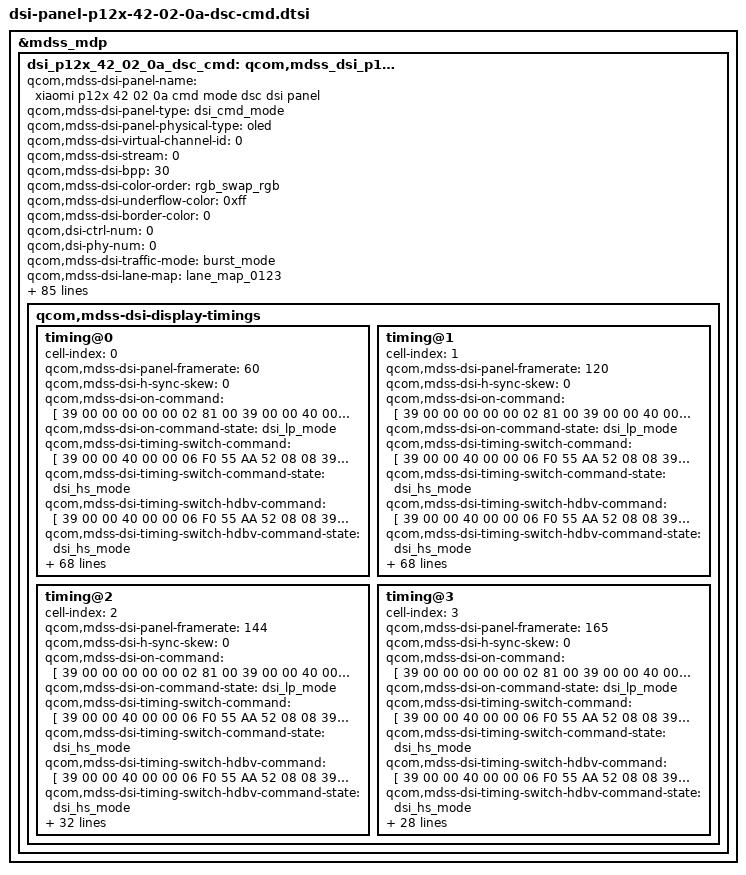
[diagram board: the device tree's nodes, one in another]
&mdss_mdp {
	dsi_p12x_42_02_0a_dsc_cmd: qcom,mdss_dsi_p12x_42_02_0a_dsc_cmd {
		qcom,mdss-dsi-panel-name = "xiaomi p12x 42 02 0a cmd mode dsc dsi panel";
		qcom,mdss-dsi-panel-type = "dsi_cmd_mode";
		qcom,mdss-dsi-panel-physical-type = "oled";
		qcom,mdss-dsi-virtual-channel-id = <0>;
		qcom,mdss-dsi-stream = <0>;
		qcom,mdss-dsi-bpp = <30>;
		qcom,mdss-dsi-color-order = "rgb_swap_rgb";
		qcom,mdss-dsi-underflow-color = <0xff>;
		qcom,mdss-dsi-border-color = <0>;
		qcom,dsi-ctrl-num = <0>;
		qcom,dsi-phy-num = <0>;
		qcom,mdss-dsi-traffic-mode = "burst_mode";
		qcom,mdss-dsi-lane-map = "lane_map_0123";
		qcom,mdss-dsi-bllp-eof-power-mode;
		qcom,mdss-dsi-bllp-power-mode;
		qcom,mdss-dsi-lane-0-state;
		qcom,mdss-dsi-lane-1-state;
		qcom,mdss-dsi-lane-2-state;
		qcom,mdss-dsi-lane-3-state;
		qcom,mdss-dsi-dma-trigger = "trigger_sw";
		qcom,mdss-dsi-mdp-trigger = "none";
		qcom,mdss-dsi-reset-sequence =<1 5>, <0 5>, <1 10>;
		qcom,mdss-pan-physical-width-dimension = <727>;
		qcom,mdss-pan-physical-height-dimension = <1575>;
		qcom,mdss-dsi-te-pin-select = <1>;
		qcom,mdss-dsi-wr-mem-start = <0x2c>;
		qcom,mdss-dsi-wr-mem-continue = <0x3c>;
		qcom,mdss-dsi-te-dcs-command = <1>;
		qcom,mdss-dsi-te-check-enable;
		qcom,mdss-dsi-te-using-te-pin;
		qcom,mdss-dsi-tx-eot-append;
		qcom,mdss-dsi-lp11-init;
		qcom,mdss-dsi-bl-inverted-dbv;
		qcom,mdss-dsi-panel-dimming-enabled;
		qcom,bl-update-flag = "delay_until_first_frame";
		qcom,mdss-dsi-panel-hdr-enabled;
		qcom,mdss-dsi-panel-hdr-color-primaries = <14500 15500 32000
			17000 15500 30000 8000 3000>;
		qcom,mdss-dsi-panel-peak-brightness = <32000000>;
		qcom,mdss-dsi-panel-blackness-level = <3230>;
		qcom,mdss-dsi-dma-schedule-line = <1>;
		qcom,mdss-dsi-dma-schedule-window = <50>;
		mi,panel-id = <0x50313258 0x0042020A>;
		mi,panel-on-dimming-delay = <120>;

		/* IRQF_ONESHOT | IRQF_TRIGGER_LOW */
		mi,esd-err-irq-gpio = <&tlmm 87 0x2008>;
		mi,esd-err-irq-gpio-flag = <0x2008>;

		mi,mdss-dsi-panel-wp-read-command = [06 01 00 01 00 00 01 5C];
		mi,mdss-dsi-panel-wp-read-command-state = "dsi_hs_mode";
		mi,mdss-dsi-panel-wp-read-length = <8>;

		mi,mdss-dsi-panel-cell-id-read-command = [06 01 00 01 00 00 01 5A];
		mi,mdss-dsi-panel-cell-id-read-command-state = "dsi_hs_mode";
		mi,mdss-dsi-panel-cell-id-read-length = <14>;
		mi,max-brightness-clone = <16383>;
		mi,mdss-dsi-fac-bl-max-level = <8191>;
		mi,mdss-fac-brightness-max-level = <8191>;
		mi,flatmode-status-check-enabled;
		mi,mdss-dsi-panel-flatmode-status-offset-command = [
 			39 00 00 00 00 00 03 F0 AA 11
 		];
		mi,mdss-dsi-panel-flatmode-status-offset-command-state = "dsi_hs_mode";
		mi,mdss-dsi-panel-flatmode-status-command = [
				06 01 00 01 00 00 01 D5
		];
		mi,mdss-dsi-panel-flatmode-status-command-state = "dsi_hs_mode";
		mi,mdss-dsi-panel-flatmode-status-read-length = <1>;
		mi,mdss-dsi-panel-flatmode-on-status-value = <0x13>;

		mi,doze-hbm-dbv-level = <690>;
		mi,doze-lbm-dbv-level = <101>;
		mi,ddic-round-corner-enabled;
		qcom,mdss-disable-cesta-hw-sleep;

		qcom,mdss-dsi-display-timings {
			timing@0 {
				#include "dsi-panel-p12x-42-02-0a-dsc-cmd-common.dtsi"
				cell-index = <0>;
				qcom,mdss-dsi-panel-framerate = <60>;
				qcom,mdss-dsi-h-sync-skew = <0>;
				qcom,mdss-dsi-on-command = [
					39 00 00 00 00 00 02 81 00
					39 00 00 40 00 00 06 F0 55 AA 52 08 00
					39 00 00 40 00 00 02 6F 78
					39 00 00 40 00 00 18 B0 11 00 2A 00 C2 01 DA 03 7C 05 B1 08 80 0B EE 0F FF 05 55 05 56 05 55
					39 00 00 40 00 00 02 6F 6F
					39 00 00 40 00 00 07 B0 02 80 05 00 02 80
					39 00 00 40 00 00 06 F0 55 AA 52 08 08
					39 00 00 40 00 00 17 C1 8C FF CC FF FF CC FF FF CC FF FF EE 7F 7F EE 7F 7F FF 7F FF 0E 7F
					39 00 00 40 00 00 02 6F 20
					39 00 00 40 00 00 04 C1 4F 00 FF
					39 00 00 40 00 00 02 6F 23
					39 00 00 00 00 00 15 C1 0C FF CC FF FF CC FF FF CC FF FF EE 7F 7F EE 7F 7F CF 7F 30
					39 00 00 40 00 00 06 F0 55 AA 52 08 00
					39 00 00 40 00 00 02 C7 44
					39 00 00 40 00 00 02 6F 31
					39 00 00 00 00 00 03 C0 01 23
					39 00 00 40 00 00 02 6F 35
					39 00 00 00 00 00 03 C0 00 00
					39 00 00 40 00 00 06 F0 55 AA 52 08 04
					39 00 00 00 00 00 02 C0 20
					39 00 00 40 00 00 06 F0 55 AA 52 08 04
					39 00 00 40 00 00 02 B1 01
					39 00 00 40 00 00 02 6F 07
					39 00 00 40 00 00 04 B1 00 02 1C
					39 00 00 40 00 00 02 6F 0A
					39 00 00 40 00 00 02 B1 20
					39 00 00 40 00 00 02 6F 0B
					39 00 00 40 00 00 02 B1 02
					39 00 00 40 00 00 02 C4 10
					39 00 00 40 00 00 02 6F 02
					39 00 00 40 00 00 03 B5 14 23
					39 00 00 40 00 00 02 6F 06
					39 00 00 40 00 00 02 B5 00
					39 00 00 40 00 00 02 6F 19
					39 00 00 00 00 00 06 B8 24 50 00  35 9A
					39 00 00 40 00 00 05 2A 00 00 04 FF
					39 00 00 00 00 00 05 2B 00 00 0A D3
					39 00 00 40 00 00 03 90 03 43
					39 00 00 00 00 00 13 91 AB A8 00 0C C2 00 02 41 01 38 00 08 08 BB 07 21 10 F0
					39 00 00 40 00 00 02 2F 00
					39 00 00 40 00 00 03 5F 00 40
					39 00 00 00 00 00 02 35 00
					39 00 00 40 00 00 06 F0 55 AA 52 08 00
					39 00 00 40 00 00 05 BE 47 46 49 4C
					39 00 00 40 00 00 02 6F 26
					39 00 00 40 00 00 08 44 00 33 00 33 4B 03 A4
					39 00 00 40 00 00 02 6F 34
					39 00 00 40 00 00 08 44 00 0C 00 0C 4B 03 A4
					39 00 00 40 00 00 02 6F 02
					39 00 00 40 00 00 02 35 00
					39 00 00 40 00 00 02 6F 14
					39 00 00 40 00 00 04 35 63 E3 7D
					39 00 00 40 00 00 02 6F 2D
					39 00 00 40 00 00 08 44 00 AB 00 AB AB 03 AB
					39 00 00 40 00 00 02 6F 3B
					39 00 00 40 00 00 08 44 00 2C 00 2C 2C 03 AB
					39 00 00 40 00 00 02 6F 02
					39 00 00 40 00 00 02 35 00
					39 00 00 40 00 00 06 F0 55 AA 52 08 00
					39 00 00 40 00 00 02 6F 11
					39 00 00 00 00 00 02 BE 5F
					39 00 00 40 00 00 05 FF AA 55 A5 80
					39 00 00 40 00 00 02 6F 07
					39 00 00 40 00 00 02 F8 4D
					39 00 00 40 00 00 02 6F 23
					39 00 00 00 00 00 02 F8 4D
					39 00 00 40 00 00 05 FF AA 55 A5 81
					39 00 00 40 00 00 02 6F 0D
					39 00 00 40 00 00 02 FD 40
					39 00 00 40 00 00 03 51 00 05
					39 00 00 40 00 00 02 A2 03
					39 00 00 00 00 00 06 A3 84 02 2B 02 2B
					39 00 00 40 00 00 02 6F 04
					39 00 00 00 00 00 03 51 3F FF
					39 00 00 40 00 00 06 F0 55 AA 52 08 00
					39 00 00 40 00 00 02 6F 01
					39 00 00 40 00 00 02 BE 45
					39 00 00 40 00 00 02 6F 05
					39 00 00 40 00 00 02 BE 88
					39 00 00 00 00 00 02 53 20
					/* Video trim setting start */
					39 00 00 40 00 00 05 FF AA 55 A5 80
					39 00 00 40 00 00 02 6F 07
					39 00 00 40 00 00 02 F8 4D
					39 00 00 40 00 00 02 6F 23
					39 00 00 00 00 00 02 F8 4D
					39 00 00 40 00 00 06 F0 55 AA 52 08 01
					39 00 00 40 00 00 02 6F 2F
					39 00 00 40 00 00 02 C3 44
					39 00 00 40 00 00 02 6F 00
					39 00 00 40 00 00 02 C3 99
					39 00 00 40 00 00 02 6F 30
					39 00 00 40 00 00 02 C3 00
					39 00 00 40 00 00 02 6F 0B
					39 00 00 00 00 00 04 C3 3F 28 5B
					39 00 00 40 00 00 02 6F 11
					39 00 00 00 00 00 04 C3 3F 34 5B
					39 00 00 40 00 00 02 6F 17
					39 00 00 00 00 00 04 C3 3F 3C 5B
					39 00 00 40 00 00 02 6F 1D
					39 00 00 00 00 00 04 C3 3F 26 5B
					39 00 00 40 00 00 02 6F 23
					39 00 00 00 00 00 04 C3 3F 2F 5B
					39 00 00 40 00 00 02 6F 0E
					39 00 00 00 00 00 04 C3 3F 32 FF
					39 00 00 40 00 00 02 6F 14
					39 00 00 00 00 00 04 C3 3F 32 FF
					39 00 00 40 00 00 02 6F 1A
					39 00 00 00 00 00 04 C3 3F 32 FF
					39 00 00 40 00 00 02 6F 20
					39 00 00 00 00 00 04 C3 3F 32 FF
					39 00 00 40 00 00 02 6F 26
					39 00 00 00 00 00 04 C3 3F 32 FF
					39 00 00 40 00 00 02 6F 29
					39 00 00 00 00 00 04 C3 11 11 01
					39 00 00 40 00 00 02 6F 2C
					39 00 00 00 00 00 04 C3 00 00 00
					39 00 00 40 00 00 02 6F 31
					39 00 00 00 00 00 03 C3 AA 02
					39 00 00 40 00 00 02 6F 33
					39 00 00 00 00 00 03 C3 AA 02
					39 00 00 40 00 00 02 6F 04
					39 00 00 40 00 00 02 C3 19
					39 00 00 40 00 00 02 6F 09
					39 00 00 40 00 00 02 C3 19
					39 00 00 40 00 00 02 6F 01
					39 00 00 40 00 00 02 C3 09
					39 00 00 40 00 00 02 6F 06
					39 00 00 40 00 00 02 C3 09
					39 00 00 40 00 00 02 6F 02
					39 00 00 00 00 00 03 C3 02 81
					39 00 00 40 00 00 02 6F 08
					39 00 00 00 00 00 02 C3 81
					/* Video trim setting end */
					39 00 00 40 00 00 06 F0 55 AA 52 08 00
					39 00 00 40 00 00 02 6F DF
					39 00 00 40 00 00 06 B2 00 01 00 26 01
					39 00 00 40 00 00 02 6F 2B
					39 00 00 40 00 00 15 B2 00 00 2E B3 2E B3 2E B3 3F FF 3F FF 3F FF 3F FF 3F FF 3F FF
					39 00 00 40 00 00 02 6F 34
					39 00 00 00 00 00 15 B3 00 01 00 05 00 05 00 26 00 26 00 26 00 26 00 26 00 26 00 26
					39 00 00 00 5A 00 02 11 00
					39 00 00 00 00 00 02 29 00
					39 00 00 40 00 00 13 A3 84 02 2B 02 2B 02 04 B5 02 03 00 03 00 00 00 00 00 00
					39 00 00 40 00 00 02 6F 12
					39 00 00 40 00 00 0E A3 01 00 9D 00 00 AA 00 00 00 00 00 00 00
					39 00 00 40 00 00 02 6F 53
					39 00 00 40 00 00 0E A3 02 04 B5 02 03 00 0C 00 00 00 00 00 00
					39 00 00 40 00 00 02 6F 60
					39 00 00 00 00 00 0E A3 01 00 9D 00 00 AA 00 00 00 00 00 00 00
		          ];
				qcom,mdss-dsi-on-command-state = "dsi_lp_mode";
				qcom,mdss-dsi-timing-switch-command = [
					39 00 00 40 00 00 06 F0 55 AA 52 08 08
					39 00 00 40 00 00 02 6F 10
					39 00 00 40 00 00 11 B7 00 00 00 00 00 00 00 00 06 F4 06 F4 07 1C 07 1C
					39 00 00 40 00 00 02 6F 20
					39 00 00 40 00 00 0F B7 07 58 07 58 07 94 07 94 08 00 08 00 0A 10
					39 00 00 40 00 00 02 6F 23
					39 00 00 40 00 00 15 C1 0C FF CC FF FF CC FF FF CC FF FF EE 7F 7F EE 7F 7F CF 7F 30
					39 00 00 40 00 00 02 2F 03
					39 00 00 40 00 00 34 A9 01 00 2F 00 00 03 01 00 A2 00 27 03 02 01 DD 02 03 00 00 00 00 00 00 00 00 02 04 B5 01 03 00 00 01 00 00 00 00 00 01 00 9D 00 00 AA 00 00 00 00 00 00 00
					39 00 00 40 00 00 13 A3 84 02 2B 02 2B 02 04 B5 02 03 00 03 00 00 00 00 00 00
					39 00 00 40 00 00 02 6F 12
					39 00 00 40 00 00 0E A3 01 00 9D 00 00 AA 00 00 00 00 00 00 00
					39 00 00 40 00 00 02 6F 53
					39 00 00 40 00 00 0E A3 02 04 B5 02 03 00 0C 00 00 00 00 00 00
					39 00 00 40 00 00 02 6F 60
					39 00 00 00 00 00 0E A3 01 00 9D 00 00 AA 00 00 00 00 00 00 00
				];
				qcom,mdss-dsi-timing-switch-command-state = "dsi_hs_mode";
				qcom,mdss-dsi-timing-switch-hdbv-command = [
					39 00 00 40 00 00 06 F0 55 AA 52 08 08
					39 00 00 40 00 00 02 6F 10
					39 00 00 40 00 00 11 B7 00 00 00 00 00 00 00 00 06 F4 06 F4 07 1C 07 1C
					39 00 00 40 00 00 02 6F 20
					39 00 00 40 00 00 0F B7 07 58 07 58 07 94 07 94 08 00 08 00 0A 10
					39 00 00 40 00 00 02 6F 23
					39 00 00 40 00 00 15 C1 0C FF CC FF FF CC FF FF CC FF FF EE 7F 7F EE 7F 7F CF 7F 30
					39 00 00 40 00 00 02 2F 03
					39 00 00 40 00 00 34 A9 01 00 2F 00 00 03 01 00 A2 00 27 03 02 01 DD 02 03 00 00 00 00 00 00 00 00 02 04 B5 01 03 00 00 05 00 00 00 00 00 01 00 9D 00 00 AA 00 00 00 00 00 00 00
					39 00 00 40 00 00 13 A3 84 02 2B 02 2B 02 04 B5 02 03 00 03 00 00 00 00 00 00
					39 00 00 40 00 00 02 6F 12
					39 00 00 40 00 00 0E A3 01 00 9D 00 00 AA 00 00 00 00 00 00 00
					39 00 00 40 00 00 02 6F 53
					39 00 00 40 00 00 0E A3 02 04 B5 02 03 00 0C 00 00 00 00 00 00
					39 00 00 40 00 00 02 6F 60
					39 00 00 00 00 00 0E A3 01 00 9D 00 00 AA 00 00 00 00 00 00 00
				];
				qcom,mdss-dsi-timing-switch-hdbv-command-state = "dsi_hs_mode";
				qcom,mdss-dsi-timing-switch-no-demura-command = [
					39 00 00 40 00 00 06 F0 55 AA 52 08 08
					39 00 00 40 00 00 02 6F 10
					39 00 00 40 00 00 11 B7 00 00 00 00 00 00 00 00 06 F4 06 F4 07 1C 07 1C
					39 00 00 40 00 00 02 6F 20
					39 00 00 40 00 00 0F B7 07 58 07 58 07 94 07 94 08 00 08 00 0A 10
					39 00 00 40 00 00 02 6F 23
					39 00 00 40 00 00 15 C1 0C FF CC FF FF CC FF FF CC FF FF EE 7F 7F EE 7F 7F CF 7F 30
					39 00 00 00 00 00 02 2F 03
				];
				qcom,mdss-dsi-timing-switch-no-demura-command-state = "dsi_hs_mode";
				qcom,mdss-dsi-nolp-command = [
					39 00 00 00 01 00 03 51 00 00
					/* AOD OFF */
					05 00 00 00 00 00 01 38
				];
				qcom,mdss-dsi-nolp-command-update = <0x51 0 2>;
				qcom,mdss-dsi-nolp-command-state = "dsi_hs_mode";

				mi,mdss-dsi-doze-hbm-command = [
					/* AOD OFF */
					39 00 00 00 01 00 03 51 02 B2
					39 00 00 00 00 00 01 38
				];
				mi,mdss-dsi-doze-hbm-command-state = "dsi_hs_mode";
				mi,mdss-dsi-doze-lbm-command = [
					/* AOD OFF */
					39 00 00 00 01 00 03 51 00 65
					39 00 00 00 00 00 01 38
				];
				mi,mdss-dsi-doze-lbm-command-state = "dsi_hs_mode";

				mi,mdss-dsi-doze-suspend-hbm-command = [
					/* AOD ON */
					39 00 00 40 00 00 01 39
					39 00 00 40 00 00 03 51 02 B2
					39 00 00 40 00 00 02 6F 04
					39 00 00 00 00 00 03 51 3F FF
				];
				mi,mdss-dsi-doze-suspend-hbm-command-state = "dsi_lp_mode";

				mi,mdss-dsi-doze-suspend-lbm-command = [
					/* AOD ON */
					39 00 00 40 00 00 01 39
					39 00 00 40 00 00 03 51 00 65
					39 00 00 40 00 00 02 6F 04
					39 00 00 00 00 00 03 51 05 54
				];
				mi,mdss-dsi-doze-suspend-lbm-command-state = "dsi_lp_mode";

				mi,mdss-dsi-doze-hbm-nolp-command = [
					/* AOD OFF */
					39 00 00 00 01 00 03 51 02 B2
					39 00 00 00 00 00 01 38
				];
				mi,mdss-dsi-doze-hbm-nolp-command-state = "dsi_lp_mode";

				mi,mdss-dsi-doze-lbm-nolp-command = [
					/* AOD OFF */
					39 00 00 00 01 00 03 51 00 65
					39 00 00 00 00 00 01 38
				];
				mi,mdss-dsi-doze-lbm-nolp-command-state = "dsi_lp_mode";

				mi,mdss-dsi-csc-by-temper-comp-off-mode-command = [
					39 00 00 00 00 00 03 81 02 97
				];
				mi,mdss-dsi-csc-by-temper-comp-off-mode-command-state = "dsi_lp_mode";

				mi,mdss-dsi-csc-by-temper-comp-26-28-mode-command = [
					39 00 00 00 00 00 03 81 02 9A
				];
				mi,mdss-dsi-csc-by-temper-comp-26-28-mode-command-state = "dsi_lp_mode";

				mi,mdss-dsi-csc-by-temper-comp-28-30-mode-command = [
					39 00 00 00 00 00 03 81 02 9C
				];
				mi,mdss-dsi-csc-by-temper-comp-28-30-mode-command-state = "dsi_lp_mode";

				mi,mdss-dsi-csc-by-temper-comp-30-32-mode-command = [
					39 00 00 00 00 00 03 81 02 9E
				];
				mi,mdss-dsi-csc-by-temper-comp-30-32-mode-command-state = "dsi_lp_mode";

				mi,mdss-dsi-csc-by-temper-comp-32-34-mode-command = [
					39 00 00 00 00 00 03 81 02 A0
				];
				mi,mdss-dsi-csc-by-temper-comp-32-34-mode-command-state = "dsi_lp_mode";

				mi,mdss-dsi-csc-by-temper-comp-34-36-mode-command = [
					39 00 00 00 00 00 03 81 02 A2
				];
				mi,mdss-dsi-csc-by-temper-comp-34-36-mode-command-state = "dsi_lp_mode";

				mi,mdss-dsi-csc-by-temper-comp-36-38-mode-command = [
					39 00 00 00 00 00 03 81 02 A4
				];
				mi,mdss-dsi-csc-by-temper-comp-36-38-mode-command-state = "dsi_lp_mode";

				mi,mdss-dsi-csc-by-temper-comp-38-40-mode-command = [
					39 00 00 00 00 00 03 81 02 A6
				];
				mi,mdss-dsi-csc-by-temper-comp-38-40-mode-command-state = "dsi_lp_mode";

				mi,mdss-dsi-csc-by-temper-comp-40-mode-command = [
					39 00 00 00 00 00 03 81 02 A8
				];
				mi,mdss-dsi-csc-by-temper-comp-40-mode-command-state = "dsi_lp_mode";
			};
			timing@1 {
				#include "dsi-panel-p12x-42-02-0a-dsc-cmd-common.dtsi"
				cell-index = <1>;
				qcom,mdss-dsi-panel-framerate = <120>;
				qcom,mdss-dsi-h-sync-skew = <0>;
				qcom,mdss-dsi-on-command = [
					39 00 00 00 00 00 02 81 00
					39 00 00 40 00 00 06 F0 55 AA 52 08 00
					39 00 00 40 00 00 02 6F 78
					39 00 00 40 00 00 18 B0 11 00 2A 00 C2 01 DA 03 7C 05 B1 08 80 0B EE 0F FF 05 55 05 56 05 55
					39 00 00 40 00 00 02 6F 6F
					39 00 00 40 00 00 07 B0 02 80 05 00 02 80
					39 00 00 40 00 00 06 F0 55 AA 52 08 08
					39 00 00 40 00 00 17 C1 8C FF CC FF FF CC FF FF CC FF FF EE 7F 7F EE 7F 7F FF 7F FF 0E 7F
					39 00 00 40 00 00 02 6F 20
					39 00 00 40 00 00 04 C1 4F 00 FF
					39 00 00 40 00 00 02 6F 23
					39 00 00 00 00 00 15 C1 0C FF CC FF FF CC FF FF CC FF FF EE 7F 7F EE 7F 7F CF 7F 30
					39 00 00 40 00 00 06 F0 55 AA 52 08 00
					39 00 00 40 00 00 02 C7 44
					39 00 00 40 00 00 02 6F 31
					39 00 00 00 00 00 03 C0 01 23
					39 00 00 40 00 00 02 6F 35
					39 00 00 00 00 00 03 C0 00 00
					39 00 00 40 00 00 06 F0 55 AA 52 08 04
					39 00 00 00 00 00 02 C0 20
					39 00 00 40 00 00 06 F0 55 AA 52 08 04
					39 00 00 40 00 00 02 B1 01
					39 00 00 40 00 00 02 6F 07
					39 00 00 40 00 00 04 B1 00 02 1C
					39 00 00 40 00 00 02 6F 0A
					39 00 00 40 00 00 02 B1 20
					39 00 00 40 00 00 02 6F 0B
					39 00 00 40 00 00 02 B1 02
					39 00 00 40 00 00 02 C4 10
					39 00 00 40 00 00 02 6F 02
					39 00 00 40 00 00 03 B5 14 23
					39 00 00 40 00 00 02 6F 06
					39 00 00 40 00 00 02 B5 00
					39 00 00 40 00 00 02 6F 19
					39 00 00 00 00 00 06 B8 24 50 00  35 9A
					39 00 00 40 00 00 05 2A 00 00 04 FF
					39 00 00 00 00 00 05 2B 00 00 0A D3
					39 00 00 40 00 00 03 90 03 43
					39 00 00 00 00 00 13 91 AB A8 00 0C C2 00 02 41 01 38 00 08 08 BB 07 21 10 F0
					39 00 00 40 00 00 02 2F 00
					39 00 00 40 00 00 03 5F 00 40
					39 00 00 00 00 00 02 35 00
					39 00 00 40 00 00 06 F0 55 AA 52 08 00
					39 00 00 40 00 00 05 BE 47 46 49 4C
					39 00 00 40 00 00 02 6F 26
					39 00 00 40 00 00 08 44 00 33 00 33 4B 03 A4
					39 00 00 40 00 00 02 6F 34
					39 00 00 40 00 00 08 44 00 0C 00 0C 4B 03 A4
					39 00 00 40 00 00 02 6F 02
					39 00 00 40 00 00 02 35 00
					39 00 00 40 00 00 02 6F 14
					39 00 00 40 00 00 04 35 63 E3 7D
					39 00 00 40 00 00 02 6F 2D
					39 00 00 40 00 00 08 44 00 AB 00 AB AB 03 AB
					39 00 00 40 00 00 02 6F 3B
					39 00 00 40 00 00 08 44 00 2C 00 2C 2C 03 AB
					39 00 00 40 00 00 02 6F 02
					39 00 00 40 00 00 02 35 00
					39 00 00 40 00 00 06 F0 55 AA 52 08 00
					39 00 00 40 00 00 02 6F 11
					39 00 00 00 00 00 02 BE 5F
					39 00 00 40 00 00 05 FF AA 55 A5 80
					39 00 00 40 00 00 02 6F 07
					39 00 00 40 00 00 02 F8 4D
					39 00 00 40 00 00 02 6F 23
					39 00 00 00 00 00 02 F8 4D
					39 00 00 40 00 00 05 FF AA 55 A5 81
					39 00 00 40 00 00 02 6F 0D
					39 00 00 40 00 00 02 FD 40
					39 00 00 40 00 00 03 51 00 05
					39 00 00 40 00 00 02 A2 03
					39 00 00 00 00 00 06 A3 84 02 2B 02 2B
					39 00 00 40 00 00 02 6F 04
					39 00 00 00 00 00 03 51 3F FF
					39 00 00 40 00 00 06 F0 55 AA 52 08 00
					39 00 00 40 00 00 02 6F 01
					39 00 00 40 00 00 02 BE 45
					39 00 00 40 00 00 02 6F 05
					39 00 00 40 00 00 02 BE 88
					39 00 00 00 00 00 02 53 20
					/* Video trim setting start */
					39 00 00 40 00 00 05 FF AA 55 A5 80
					39 00 00 40 00 00 02 6F 07
					39 00 00 40 00 00 02 F8 4D
					39 00 00 40 00 00 02 6F 23
					39 00 00 00 00 00 02 F8 4D
					39 00 00 40 00 00 06 F0 55 AA 52 08 01
					39 00 00 40 00 00 02 6F 2F
					39 00 00 40 00 00 02 C3 44
					39 00 00 40 00 00 02 6F 00
					39 00 00 40 00 00 02 C3 99
					39 00 00 40 00 00 02 6F 30
					39 00 00 40 00 00 02 C3 00
					39 00 00 40 00 00 02 6F 0B
					39 00 00 00 00 00 04 C3 3F 28 5B
					39 00 00 40 00 00 02 6F 11
					39 00 00 00 00 00 04 C3 3F 34 5B
					39 00 00 40 00 00 02 6F 17
					39 00 00 00 00 00 04 C3 3F 3C 5B
					39 00 00 40 00 00 02 6F 1D
					39 00 00 00 00 00 04 C3 3F 26 5B
					39 00 00 40 00 00 02 6F 23
					39 00 00 00 00 00 04 C3 3F 2F 5B
					39 00 00 40 00 00 02 6F 0E
					39 00 00 00 00 00 04 C3 3F 32 FF
					39 00 00 40 00 00 02 6F 14
					39 00 00 00 00 00 04 C3 3F 32 FF
					39 00 00 40 00 00 02 6F 1A
					39 00 00 00 00 00 04 C3 3F 32 FF
					39 00 00 40 00 00 02 6F 20
					39 00 00 00 00 00 04 C3 3F 32 FF
					39 00 00 40 00 00 02 6F 26
					39 00 00 00 00 00 04 C3 3F 32 FF
					39 00 00 40 00 00 02 6F 29
					39 00 00 00 00 00 04 C3 11 11 01
					39 00 00 40 00 00 02 6F 2C
					39 00 00 00 00 00 04 C3 00 00 00
					39 00 00 40 00 00 02 6F 31
					39 00 00 00 00 00 03 C3 AA 02
					39 00 00 40 00 00 02 6F 33
					39 00 00 00 00 00 03 C3 AA 02
					39 00 00 40 00 00 02 6F 04
					39 00 00 40 00 00 02 C3 19
					39 00 00 40 00 00 02 6F 09
					39 00 00 40 00 00 02 C3 19
					39 00 00 40 00 00 02 6F 01
					39 00 00 40 00 00 02 C3 09
					39 00 00 40 00 00 02 6F 06
					39 00 00 40 00 00 02 C3 09
					39 00 00 40 00 00 02 6F 02
					39 00 00 00 00 00 03 C3 02 81
					39 00 00 40 00 00 02 6F 08
					39 00 00 00 00 00 02 C3 81
					/* Video trim setting end */
					39 00 00 40 00 00 06 F0 55 AA 52 08 00
					39 00 00 40 00 00 02 6F DF
					39 00 00 40 00 00 06 B2 00 01 00 26 01
					39 00 00 40 00 00 02 6F 2B
					39 00 00 40 00 00 15 B2 00 00 2E B3 2E B3 2E B3 3F FF 3F FF 3F FF 3F FF 3F FF 3F FF
					39 00 00 40 00 00 02 6F 34
					39 00 00 00 00 00 15 B3 00 01 00 05 00 05 00 26 00 26 00 26 00 26 00 26 00 26 00 26
					39 00 00 00 5A 00 02 11 00
					39 00 00 00 00 00 02 29 00
					39 00 00 40 00 00 13 A3 84 02 2B 02 2B 02 04 B5 02 03 00 03 00 00 00 00 00 00
					39 00 00 40 00 00 02 6F 12
					39 00 00 40 00 00 0E A3 01 00 9D 00 00 AA 00 00 00 00 00 00 00
					39 00 00 40 00 00 02 6F 53
					39 00 00 40 00 00 0E A3 02 04 B5 02 03 00 0C 00 00 00 00 00 00
					39 00 00 40 00 00 02 6F 60
					39 00 00 00 00 00 0E A3 01 00 9D 00 00 AA 00 00 00 00 00 00 00
		          ];
				qcom,mdss-dsi-on-command-state = "dsi_lp_mode";
				qcom,mdss-dsi-timing-switch-command = [
					39 00 00 40 00 00 06 F0 55 AA 52 08 08
					39 00 00 40 00 00 02 6F 10
					39 00 00 40 00 00 11 B7 00 00 00 00 00 00 00 00 06 F4 06 F4 07 1C 07 1C
					39 00 00 40 00 00 02 6F 20
					39 00 00 40 00 00 0F B7 07 58 07 58 07 94 07 94 08 00 08 00 0A 10
					39 00 00 40 00 00 02 6F 23
					39 00 00 40 00 00 15 C1 0C FF CC FF FF CC FF FF CC FF FF EE 7F 7F EE 7F 7F CF 7F 30
					39 00 00 40 00 00 02 2F 00
					39 00 00 40 00 00 34 A9 01 00 2F 00 00 00 01 00 A2 00 27 03 02 01 DD 02 03 00 00 00 00 00 00 00 00 02 04 B5 01 03 00 00 01 00 00 00 00 00 01 00 9D 00 00 AA 00 00 00 00 00 00 00
					39 00 00 40 00 00 13 A3 84 02 2B 02 2B 02 04 B5 02 03 00 03 00 00 00 00 00 00
					39 00 00 40 00 00 02 6F 12
					39 00 00 40 00 00 0E A3 01 00 9D 00 00 AA 00 00 00 00 00 00 00
					39 00 00 40 00 00 02 6F 53
					39 00 00 40 00 00 0E A3 02 04 B5 02 03 00 0C 00 00 00 00 00 00
					39 00 00 40 00 00 02 6F 60
					39 00 00 00 00 00 0E A3 01 00 9D 00 00 AA 00 00 00 00 00 00 00
				];
				qcom,mdss-dsi-timing-switch-command-state = "dsi_hs_mode";
				qcom,mdss-dsi-timing-switch-hdbv-command = [
					39 00 00 40 00 00 06 F0 55 AA 52 08 08
					39 00 00 40 00 00 02 6F 10
					39 00 00 40 00 00 11 B7 00 00 00 00 00 00 00 00 06 F4 06 F4 07 1C 07 1C
					39 00 00 40 00 00 02 6F 20
					39 00 00 40 00 00 0F B7 07 58 07 58 07 94 07 94 08 00 08 00 0A 10
					39 00 00 40 00 00 02 6F 23
					39 00 00 40 00 00 15 C1 0C FF CC FF FF CC FF FF CC FF FF EE 7F 7F EE 7F 7F CF 7F 30
					39 00 00 40 00 00 02 2F 00
					39 00 00 40 00 00 34 A9 01 00 2F 00 00 00 01 00 A2 00 27 03 02 01 DD 02 03 00 00 00 00 00 00 00 00 02 04 B5 01 03 00 00 05 00 00 00 00 00 01 00 9D 00 00 AA 00 00 00 00 00 00 00
					39 00 00 40 00 00 13 A3 84 02 2B 02 2B 02 04 B5 02 03 00 03 00 00 00 00 00 00
					39 00 00 40 00 00 02 6F 12
					39 00 00 40 00 00 0E A3 01 00 9D 00 00 AA 00 00 00 00 00 00 00
					39 00 00 40 00 00 02 6F 53
					39 00 00 40 00 00 0E A3 02 04 B5 02 03 00 0C 00 00 00 00 00 00
					39 00 00 40 00 00 02 6F 60
					39 00 00 00 00 00 0E A3 01 00 9D 00 00 AA 00 00 00 00 00 00 00
				];
				qcom,mdss-dsi-timing-switch-hdbv-command-state = "dsi_hs_mode";
				qcom,mdss-dsi-timing-switch-no-demura-command = [
					39 00 00 40 00 00 06 F0 55 AA 52 08 08
					39 00 00 40 00 00 02 6F 10
					39 00 00 40 00 00 11 B7 00 00 00 00 00 00 00 00 06 F4 06 F4 07 1C 07 1C
					39 00 00 40 00 00 02 6F 20
					39 00 00 40 00 00 0F B7 07 58 07 58 07 94 07 94 08 00 08 00 0A 10
					39 00 00 40 00 00 02 6F 23
					39 00 00 40 00 00 15 C1 0C FF CC FF FF CC FF FF CC FF FF EE 7F 7F EE 7F 7F CF 7F 30
					39 00 00 00 00 00 02 2F 00
				];
				qcom,mdss-dsi-timing-switch-no-demura-command-state = "dsi_hs_mode";
				qcom,mdss-dsi-nolp-command = [
					39 00 00 00 01 00 03 51 00 00
					/* AOD OFF */
					05 00 00 00 00 00 01 38
				];
				qcom,mdss-dsi-nolp-command-update = <0x51 0 2>;
				qcom,mdss-dsi-nolp-command-state = "dsi_hs_mode";

				mi,mdss-dsi-doze-hbm-command = [
					/* AOD OFF */
					39 00 00 00 01 00 03 51 02 B2
					39 00 00 00 00 00 01 38
				];
				mi,mdss-dsi-doze-hbm-command-state = "dsi_hs_mode";
				mi,mdss-dsi-doze-lbm-command = [
					/* AOD OFF */
					39 00 00 00 01 00 03 51 00 65
					39 00 00 00 00 00 01 38
				];
				mi,mdss-dsi-doze-lbm-command-state = "dsi_hs_mode";

				mi,mdss-dsi-doze-suspend-hbm-command = [
					/* AOD ON */
					39 00 00 40 00 00 01 39
					39 00 00 40 00 00 03 51 02 B2
					39 00 00 40 00 00 02 6F 04
					39 00 00 00 00 00 03 51 3F FF
				];
				mi,mdss-dsi-doze-suspend-hbm-command-state = "dsi_lp_mode";

				mi,mdss-dsi-doze-suspend-lbm-command = [
					/* AOD ON */
					39 00 00 40 00 00 01 39
					39 00 00 40 00 00 03 51 00 65
					39 00 00 40 00 00 02 6F 04
					39 00 00 00 00 00 03 51 05 54
				];
				mi,mdss-dsi-doze-suspend-lbm-command-state = "dsi_lp_mode";

				mi,mdss-dsi-doze-hbm-nolp-command = [
					/* AOD OFF */
					39 00 00 00 01 00 03 51 02 B2
					39 00 00 00 00 00 01 38
				];
				mi,mdss-dsi-doze-hbm-nolp-command-state = "dsi_lp_mode";

				mi,mdss-dsi-doze-lbm-nolp-command = [
					/* AOD OFF */
					39 00 00 00 01 00 03 51 00 65
					39 00 00 00 00 00 01 38
				];
				mi,mdss-dsi-doze-lbm-nolp-command-state = "dsi_lp_mode";

				mi,mdss-dsi-csc-by-temper-comp-off-mode-command = [
					39 00 00 00 00 00 03 81 02 17
				];
				mi,mdss-dsi-csc-by-temper-comp-off-mode-command-state = "dsi_lp_mode";

				mi,mdss-dsi-csc-by-temper-comp-26-28-mode-command = [
					39 00 00 00 00 00 03 81 02 1A
				];
				mi,mdss-dsi-csc-by-temper-comp-26-28-mode-command-state = "dsi_lp_mode";

				mi,mdss-dsi-csc-by-temper-comp-28-30-mode-command = [
					39 00 00 00 00 00 03 81 02 1C
				];
				mi,mdss-dsi-csc-by-temper-comp-28-30-mode-command-state = "dsi_lp_mode";

				mi,mdss-dsi-csc-by-temper-comp-30-32-mode-command = [
					39 00 00 00 00 00 03 81 02 1E
				];
				mi,mdss-dsi-csc-by-temper-comp-30-32-mode-command-state = "dsi_lp_mode";

				mi,mdss-dsi-csc-by-temper-comp-32-34-mode-command = [
					39 00 00 00 00 00 03 81 02 20
				];
				mi,mdss-dsi-csc-by-temper-comp-32-34-mode-command-state = "dsi_lp_mode";

				mi,mdss-dsi-csc-by-temper-comp-34-36-mode-command = [
					39 00 00 00 00 00 03 81 02 22
				];
				mi,mdss-dsi-csc-by-temper-comp-34-36-mode-command-state = "dsi_lp_mode";

				mi,mdss-dsi-csc-by-temper-comp-36-38-mode-command = [
					39 00 00 00 00 00 03 81 02 24
				];
				mi,mdss-dsi-csc-by-temper-comp-36-38-mode-command-state = "dsi_lp_mode";

				mi,mdss-dsi-csc-by-temper-comp-38-40-mode-command = [
					39 00 00 00 00 00 03 81 02 26
				];
				mi,mdss-dsi-csc-by-temper-comp-38-40-mode-command-state = "dsi_lp_mode";

				mi,mdss-dsi-csc-by-temper-comp-40-mode-command = [
					39 00 00 00 00 00 03 81 02 28
				];
				mi,mdss-dsi-csc-by-temper-comp-40-mode-command-state = "dsi_lp_mode";
			};
			timing@2 {
				#include "dsi-panel-p12x-42-02-0a-dsc-cmd-common.dtsi"
				cell-index = <2>;
				qcom,mdss-dsi-panel-framerate = <144>;
				qcom,mdss-dsi-h-sync-skew = <0>;
				qcom,mdss-dsi-on-command = [
					39 00 00 00 00 00 02 81 00
					39 00 00 40 00 00 06 F0 55 AA 52 08 00
					39 00 00 40 00 00 02 6F 78
					39 00 00 40 00 00 18 B0 11 00 2A 00 C2 01 DA 03 7C 05 B1 08 80 0B EE 0F FF 05 55 05 56 05 55
					39 00 00 40 00 00 02 6F 6F
					39 00 00 40 00 00 07 B0 02 80 05 00 02 80
					39 00 00 40 00 00 06 F0 55 AA 52 08 08
					39 00 00 40 00 00 17 C1 8C FF CC FF FF CC FF FF CC FF FF EE 7F 7F EE 7F 7F FF 7F FF 0E 7F
					39 00 00 40 00 00 02 6F 20
					39 00 00 40 00 00 04 C1 4F 00 FF
					39 00 00 40 00 00 02 6F 23
					39 00 00 00 00 00 15 C1 0C FF CC FF FF CC FF FF CC FF FF EE 7F 7F EE 7F 7F CF 7F 30
					39 00 00 40 00 00 06 F0 55 AA 52 08 00
					39 00 00 40 00 00 02 C7 44
					39 00 00 40 00 00 02 6F 31
					39 00 00 00 00 00 03 C0 01 23
					39 00 00 40 00 00 02 6F 35
					39 00 00 00 00 00 03 C0 00 00
					39 00 00 40 00 00 06 F0 55 AA 52 08 04
					39 00 00 00 00 00 02 C0 20
					39 00 00 40 00 00 06 F0 55 AA 52 08 04
					39 00 00 40 00 00 02 B1 01
					39 00 00 40 00 00 02 6F 07
					39 00 00 40 00 00 04 B1 00 02 1C
					39 00 00 40 00 00 02 6F 0A
					39 00 00 40 00 00 02 B1 20
					39 00 00 40 00 00 02 6F 0B
					39 00 00 40 00 00 02 B1 02
					39 00 00 40 00 00 02 C4 10
					39 00 00 40 00 00 02 6F 02
					39 00 00 40 00 00 03 B5 14 23
					39 00 00 40 00 00 02 6F 06
					39 00 00 40 00 00 02 B5 00
					39 00 00 40 00 00 02 6F 19
					39 00 00 00 00 00 06 B8 24 50 00  35 9A
					39 00 00 40 00 00 05 2A 00 00 04 FF
					39 00 00 00 00 00 05 2B 00 00 0A D3
					39 00 00 40 00 00 03 90 03 43
					39 00 00 00 00 00 13 91 AB A8 00 0C C2 00 02 41 01 38 00 08 08 BB 07 21 10 F0
					39 00 00 40 00 00 02 2F 00
					39 00 00 40 00 00 03 5F 00 40
					39 00 00 00 00 00 02 35 00
					39 00 00 40 00 00 06 F0 55 AA 52 08 00
					39 00 00 40 00 00 05 BE 47 46 49 4C
					39 00 00 40 00 00 02 6F 26
					39 00 00 40 00 00 08 44 00 33 00 33 4B 03 A4
					39 00 00 40 00 00 02 6F 34
					39 00 00 40 00 00 08 44 00 0C 00 0C 4B 03 A4
					39 00 00 40 00 00 02 6F 02
					39 00 00 40 00 00 02 35 00
					39 00 00 40 00 00 02 6F 14
					39 00 00 40 00 00 04 35 63 E3 7D
					39 00 00 40 00 00 02 6F 2D
					39 00 00 40 00 00 08 44 00 AB 00 AB AB 03 AB
					39 00 00 40 00 00 02 6F 3B
					39 00 00 40 00 00 08 44 00 2C 00 2C 2C 03 AB
					39 00 00 40 00 00 02 6F 02
					39 00 00 40 00 00 02 35 00
					39 00 00 40 00 00 06 F0 55 AA 52 08 00
					39 00 00 40 00 00 02 6F 11
					39 00 00 00 00 00 02 BE 5F
					39 00 00 40 00 00 05 FF AA 55 A5 80
					39 00 00 40 00 00 02 6F 07
					39 00 00 40 00 00 02 F8 4D
					39 00 00 40 00 00 02 6F 23
					39 00 00 00 00 00 02 F8 4D
					39 00 00 40 00 00 05 FF AA 55 A5 81
					39 00 00 40 00 00 02 6F 0D
					39 00 00 40 00 00 02 FD 40
					39 00 00 40 00 00 03 51 00 05
					39 00 00 40 00 00 02 A2 03
					39 00 00 00 00 00 06 A3 84 02 2B 02 2B
					39 00 00 40 00 00 02 6F 04
					39 00 00 00 00 00 03 51 3F FF
					39 00 00 40 00 00 06 F0 55 AA 52 08 00
					39 00 00 40 00 00 02 6F 01
					39 00 00 40 00 00 02 BE 45
					39 00 00 40 00 00 02 6F 05
					39 00 00 40 00 00 02 BE 88
					39 00 00 00 00 00 02 53 20
					/* Video trim setting start */
					39 00 00 40 00 00 05 FF AA 55 A5 80
					39 00 00 40 00 00 02 6F 07
					39 00 00 40 00 00 02 F8 4D
					39 00 00 40 00 00 02 6F 23
					39 00 00 00 00 00 02 F8 4D
					39 00 00 40 00 00 06 F0 55 AA 52 08 01
					39 00 00 40 00 00 02 6F 2F
					39 00 00 40 00 00 02 C3 44
					39 00 00 40 00 00 02 6F 00
					39 00 00 40 00 00 02 C3 99
					39 00 00 40 00 00 02 6F 30
					39 00 00 40 00 00 02 C3 00
					39 00 00 40 00 00 02 6F 0B
					39 00 00 00 00 00 04 C3 3F 28 5B
					39 00 00 40 00 00 02 6F 11
					39 00 00 00 00 00 04 C3 3F 34 5B
					39 00 00 40 00 00 02 6F 17
					39 00 00 00 00 00 04 C3 3F 3C 5B
					39 00 00 40 00 00 02 6F 1D
					39 00 00 00 00 00 04 C3 3F 26 5B
					39 00 00 40 00 00 02 6F 23
					39 00 00 00 00 00 04 C3 3F 2F 5B
					39 00 00 40 00 00 02 6F 0E
					39 00 00 00 00 00 04 C3 3F 32 FF
					39 00 00 40 00 00 02 6F 14
					39 00 00 00 00 00 04 C3 3F 32 FF
					39 00 00 40 00 00 02 6F 1A
					39 00 00 00 00 00 04 C3 3F 32 FF
					39 00 00 40 00 00 02 6F 20
					39 00 00 00 00 00 04 C3 3F 32 FF
					39 00 00 40 00 00 02 6F 26
					39 00 00 00 00 00 04 C3 3F 32 FF
					39 00 00 40 00 00 02 6F 29
					39 00 00 00 00 00 04 C3 11 11 01
					39 00 00 40 00 00 02 6F 2C
					39 00 00 00 00 00 04 C3 00 00 00
					39 00 00 40 00 00 02 6F 31
					39 00 00 00 00 00 03 C3 AA 02
					39 00 00 40 00 00 02 6F 33
					39 00 00 00 00 00 03 C3 AA 02
					39 00 00 40 00 00 02 6F 04
					39 00 00 40 00 00 02 C3 19
					39 00 00 40 00 00 02 6F 09
					39 00 00 40 00 00 02 C3 19
					39 00 00 40 00 00 02 6F 01
					39 00 00 40 00 00 02 C3 09
					39 00 00 40 00 00 02 6F 06
					39 00 00 40 00 00 02 C3 09
					39 00 00 40 00 00 02 6F 02
					39 00 00 00 00 00 03 C3 02 81
					39 00 00 40 00 00 02 6F 08
					39 00 00 00 00 00 02 C3 81
					/* Video trim setting end */
					39 00 00 40 00 00 06 F0 55 AA 52 08 00
					39 00 00 40 00 00 02 6F DF
					39 00 00 40 00 00 06 B2 00 01 00 26 01
					39 00 00 40 00 00 02 6F 2B
					39 00 00 40 00 00 15 B2 00 00 2E B3 2E B3 2E B3 3F FF 3F FF 3F FF 3F FF 3F FF 3F FF
					39 00 00 40 00 00 02 6F 34
					39 00 00 00 00 00 15 B3 00 01 00 05 00 05 00 26 00 26 00 26 00 26 00 26 00 26 00 26
					39 00 00 00 5A 00 02 11 00
					39 00 00 00 00 00 02 29 00
					39 00 00 40 00 00 13 A3 84 02 2B 02 2B 02 04 B5 02 03 00 03 00 00 00 00 00 00
					39 00 00 40 00 00 02 6F 12
					39 00 00 40 00 00 0E A3 01 00 9D 00 00 AA 00 00 00 00 00 00 00
					39 00 00 40 00 00 02 6F 53
					39 00 00 40 00 00 0E A3 02 04 B5 02 03 00 0C 00 00 00 00 00 00
					39 00 00 40 00 00 02 6F 60
					39 00 00 00 00 00 0E A3 01 00 9D 00 00 AA 00 00 00 00 00 00 00
		          ];
				qcom,mdss-dsi-on-command-state = "dsi_lp_mode";
				qcom,mdss-dsi-timing-switch-command = [
					39 00 00 40 00 00 06 F0 55 AA 52 08 08
					39 00 00 40 00 00 02 6F 10
					39 00 00 40 00 00 11 B7 00 00 00 00 00 00 00 00 08 FC 08 FC 09 4C 09 4C
					39 00 00 40 00 00 02 6F 20
					39 00 00 40 00 00 0F B7 09 92 09 92 09 92 09 92 0A 3A 0A 3A 0B 82
					39 00 00 40 00 00 02 6F 23
					39 00 00 40 00 00 15 C1 0C FF CC FF FF CC FF FF CC FF FF EE 7F 7F EE 7F 7F CF 7F 30
					39 00 00 40 00 00 02 2F 01
					39 00 00 40 00 00 34 A9 01 00 2F 00 00 01 01 00 A2 00 27 03 02 01 DD 02 03 00 00 00 00 00 00 00 00 02 04 B5 01 03 00 00 01 00 00 00 00 00 01 00 9D 00 00 AA 00 00 00 00 00 00 00
					39 00 00 40 00 00 13 A3 84 02 2B 02 2B 02 04 B5 02 03 00 03 00 00 00 00 00 00
					39 00 00 40 00 00 02 6F 12
					39 00 00 40 00 00 0E A3 01 00 9D 00 00 AA 00 00 00 00 00 00 00
					39 00 00 40 00 00 02 6F 53
					39 00 00 40 00 00 0E A3 02 04 B5 02 03 00 0C 00 00 00 00 00 00
					39 00 00 40 00 00 02 6F 60
					39 00 00 00 00 00 0E A3 01 00 9D 00 00 AA 00 00 00 00 00 00 00
				];
				qcom,mdss-dsi-timing-switch-command-state = "dsi_hs_mode";
				qcom,mdss-dsi-timing-switch-hdbv-command = [
					39 00 00 40 00 00 06 F0 55 AA 52 08 08
					39 00 00 40 00 00 02 6F 10
					39 00 00 40 00 00 11 B7 00 00 00 00 00 00 00 00 08 FC 08 FC 09 4C 09 4C
					39 00 00 40 00 00 02 6F 20
					39 00 00 40 00 00 0F B7 09 92 09 92 09 92 09 92 0A 3A 0A 3A 0B 82
					39 00 00 40 00 00 02 6F 23
					39 00 00 40 00 00 15 C1 0C FF CC FF FF CC FF FF CC FF FF EE 7F 7F EE 7F 7F CF 7F 30
					39 00 00 40 00 00 02 2F 01
					39 00 00 40 00 00 34 A9 01 00 2F 00 00 01 01 00 A2 00 27 03 02 01 DD 02 03 00 00 00 00 00 00 00 00 02 04 B5 01 03 00 00 05 00 00 00 00 00 01 00 9D 00 00 AA 00 00 00 00 00 00 00
					39 00 00 40 00 00 13 A3 84 02 2B 02 2B 02 04 B5 02 03 00 03 00 00 00 00 00 00
					39 00 00 40 00 00 02 6F 12
					39 00 00 40 00 00 0E A3 01 00 9D 00 00 AA 00 00 00 00 00 00 00
					39 00 00 40 00 00 02 6F 53
					39 00 00 40 00 00 0E A3 02 04 B5 02 03 00 0C 00 00 00 00 00 00
					39 00 00 40 00 00 02 6F 60
					39 00 00 00 00 00 0E A3 01 00 9D 00 00 AA 00 00 00 00 00 00 00
				];
				qcom,mdss-dsi-timing-switch-hdbv-command-state = "dsi_hs_mode";
				qcom,mdss-dsi-timing-switch-no-demura-command = [
					39 00 00 40 00 00 06 F0 55 AA 52 08 08
					39 00 00 40 00 00 02 6F 10
					39 00 00 40 00 00 11 B7 00 00 00 00 00 00 00 00 08 FC 08 FC 09 4C 09 4C
					39 00 00 40 00 00 02 6F 20
					39 00 00 40 00 00 0F B7 09 92 09 92 09 92 09 92 0A 3A 0A 3A 0B 82
					39 00 00 40 00 00 02 6F 23
					39 00 00 40 00 00 15 C1 0C FF CC FF FF CC FF FF CC FF FF EE 7F 7F EE 7F 7F CF 7F 30
					39 00 00 00 00 00 02 2F 01
				];
				qcom,mdss-dsi-timing-switch-no-demura-command-state = "dsi_hs_mode";
				qcom,mdss-dsi-nolp-command = [
					39 00 00 00 01 00 03 51 00 00
					/* AOD OFF */
					05 00 00 00 00 00 01 38
				];
				qcom,mdss-dsi-nolp-command-update = <0x51 0 2>;
				qcom,mdss-dsi-nolp-command-state = "dsi_hs_mode";

				mi,mdss-dsi-doze-hbm-command = [
					/* AOD OFF */
					39 00 00 00 01 00 03 51 02 B2
					39 00 00 00 00 00 01 38
				];
				mi,mdss-dsi-doze-hbm-command-state = "dsi_hs_mode";
				mi,mdss-dsi-doze-lbm-command = [
					/* AOD OFF */
					39 00 00 00 01 00 03 51 00 65
					39 00 00 00 00 00 01 38
				];
				mi,mdss-dsi-doze-lbm-command-state = "dsi_hs_mode";

				mi,mdss-dsi-doze-suspend-hbm-command = [
					/* AOD ON */
					39 00 00 40 00 00 01 39
					39 00 00 40 00 00 03 51 02 B2
					39 00 00 40 00 00 02 6F 04
					39 00 00 00 00 00 03 51 3F FF
				];
				mi,mdss-dsi-doze-suspend-hbm-command-state = "dsi_lp_mode";

				mi,mdss-dsi-doze-suspend-lbm-command = [
					/* AOD ON */
					39 00 00 40 00 00 01 39
					39 00 00 40 00 00 03 51 00 65
					39 00 00 40 00 00 02 6F 04
					39 00 00 00 00 00 03 51 05 54
				];
				mi,mdss-dsi-doze-suspend-lbm-command-state = "dsi_lp_mode";

				mi,mdss-dsi-doze-hbm-nolp-command = [
					/* AOD OFF */
					39 00 00 00 01 00 03 51 02 B2
					39 00 00 00 00 00 01 38
				];
				mi,mdss-dsi-doze-hbm-nolp-command-state = "dsi_lp_mode";

				mi,mdss-dsi-doze-lbm-nolp-command = [
					/* AOD OFF */
					39 00 00 00 01 00 03 51 00 65
					39 00 00 00 00 00 01 38
				];
				mi,mdss-dsi-doze-lbm-nolp-command-state = "dsi_lp_mode";
			};
			timing@3 {
				#include "dsi-panel-p12x-42-02-0a-dsc-cmd-common.dtsi"
				cell-index = <3>;
				qcom,mdss-dsi-panel-framerate = <165>;
				qcom,mdss-dsi-h-sync-skew = <0>;
				qcom,mdss-dsi-on-command = [
					39 00 00 00 00 00 02 81 00
					39 00 00 40 00 00 06 F0 55 AA 52 08 00
					39 00 00 40 00 00 02 6F 78
					39 00 00 40 00 00 18 B0 11 00 2A 00 C2 01 DA 03 7C 05 B1 08 80 0B EE 0F FF 05 55 05 56 05 55
					39 00 00 40 00 00 02 6F 6F
					39 00 00 40 00 00 07 B0 02 80 05 00 02 80
					39 00 00 40 00 00 06 F0 55 AA 52 08 08
					39 00 00 40 00 00 17 C1 8C FF CC FF FF CC FF FF CC FF FF EE 7F 7F EE 7F 7F FF 7F FF 0E 7F
					39 00 00 40 00 00 02 6F 20
					39 00 00 40 00 00 04 C1 4F 00 FF
					39 00 00 40 00 00 02 6F 23
					39 00 00 00 00 00 15 C1 0C FF CC FF FF CC FF FF CC FF FF EE 7F 7F EE 7F 7F CF 7F 30
					39 00 00 40 00 00 06 F0 55 AA 52 08 00
					39 00 00 40 00 00 02 C7 44
					39 00 00 40 00 00 02 6F 31
					39 00 00 00 00 00 03 C0 01 23
					39 00 00 40 00 00 02 6F 35
					39 00 00 00 00 00 03 C0 00 00
					39 00 00 40 00 00 06 F0 55 AA 52 08 04
					39 00 00 00 00 00 02 C0 20
					39 00 00 40 00 00 06 F0 55 AA 52 08 04
					39 00 00 40 00 00 02 B1 01
					39 00 00 40 00 00 02 6F 07
					39 00 00 40 00 00 04 B1 00 02 1C
					39 00 00 40 00 00 02 6F 0A
					39 00 00 40 00 00 02 B1 20
					39 00 00 40 00 00 02 6F 0B
					39 00 00 40 00 00 02 B1 02
					39 00 00 40 00 00 02 C4 10
					39 00 00 40 00 00 02 6F 02
					39 00 00 40 00 00 03 B5 14 23
					39 00 00 40 00 00 02 6F 06
					39 00 00 40 00 00 02 B5 00
					39 00 00 40 00 00 02 6F 19
					39 00 00 00 00 00 06 B8 24 50 00  35 9A
					39 00 00 40 00 00 05 2A 00 00 04 FF
					39 00 00 00 00 00 05 2B 00 00 0A D3
					39 00 00 40 00 00 03 90 03 43
					39 00 00 00 00 00 13 91 AB A8 00 0C C2 00 02 41 01 38 00 08 08 BB 07 21 10 F0
					39 00 00 40 00 00 02 2F 00
					39 00 00 40 00 00 03 5F 00 40
					39 00 00 00 00 00 02 35 00
					39 00 00 40 00 00 06 F0 55 AA 52 08 00
					39 00 00 40 00 00 05 BE 47 46 49 4C
					39 00 00 40 00 00 02 6F 26
					39 00 00 40 00 00 08 44 00 33 00 33 4B 03 A4
					39 00 00 40 00 00 02 6F 34
					39 00 00 40 00 00 08 44 00 0C 00 0C 4B 03 A4
					39 00 00 40 00 00 02 6F 02
					39 00 00 40 00 00 02 35 00
					39 00 00 40 00 00 02 6F 14
					39 00 00 40 00 00 04 35 63 E3 7D
					39 00 00 40 00 00 02 6F 2D
					39 00 00 40 00 00 08 44 00 AB 00 AB AB 03 AB
					39 00 00 40 00 00 02 6F 3B
					39 00 00 40 00 00 08 44 00 2C 00 2C 2C 03 AB
					39 00 00 40 00 00 02 6F 02
					39 00 00 40 00 00 02 35 00
					39 00 00 40 00 00 06 F0 55 AA 52 08 00
					39 00 00 40 00 00 02 6F 11
					39 00 00 00 00 00 02 BE 5F
					39 00 00 40 00 00 05 FF AA 55 A5 80
					39 00 00 40 00 00 02 6F 07
					39 00 00 40 00 00 02 F8 4D
					39 00 00 40 00 00 02 6F 23
					39 00 00 00 00 00 02 F8 4D
					39 00 00 40 00 00 05 FF AA 55 A5 81
					39 00 00 40 00 00 02 6F 0D
					39 00 00 40 00 00 02 FD 40
					39 00 00 40 00 00 03 51 00 05
					39 00 00 40 00 00 02 A2 03
					39 00 00 00 00 00 06 A3 84 02 2B 02 2B
					39 00 00 40 00 00 02 6F 04
					39 00 00 00 00 00 03 51 3F FF
					39 00 00 40 00 00 06 F0 55 AA 52 08 00
					39 00 00 40 00 00 02 6F 01
					39 00 00 40 00 00 02 BE 45
					39 00 00 40 00 00 02 6F 05
					39 00 00 40 00 00 02 BE 88
					39 00 00 00 00 00 02 53 20
					/* Video trim setting start */
					39 00 00 40 00 00 05 FF AA 55 A5 80
					39 00 00 40 00 00 02 6F 07
					39 00 00 40 00 00 02 F8 4D
					39 00 00 40 00 00 02 6F 23
					39 00 00 00 00 00 02 F8 4D
					39 00 00 40 00 00 06 F0 55 AA 52 08 01
					39 00 00 40 00 00 02 6F 2F
					39 00 00 40 00 00 02 C3 44
					39 00 00 40 00 00 02 6F 00
					39 00 00 40 00 00 02 C3 99
					39 00 00 40 00 00 02 6F 30
					39 00 00 40 00 00 02 C3 00
					39 00 00 40 00 00 02 6F 0B
					39 00 00 00 00 00 04 C3 3F 28 5B
					39 00 00 40 00 00 02 6F 11
					39 00 00 00 00 00 04 C3 3F 34 5B
					39 00 00 40 00 00 02 6F 17
					39 00 00 00 00 00 04 C3 3F 3C 5B
					39 00 00 40 00 00 02 6F 1D
					39 00 00 00 00 00 04 C3 3F 26 5B
					39 00 00 40 00 00 02 6F 23
					39 00 00 00 00 00 04 C3 3F 2F 5B
					39 00 00 40 00 00 02 6F 0E
					39 00 00 00 00 00 04 C3 3F 32 FF
					39 00 00 40 00 00 02 6F 14
					39 00 00 00 00 00 04 C3 3F 32 FF
					39 00 00 40 00 00 02 6F 1A
					39 00 00 00 00 00 04 C3 3F 32 FF
					39 00 00 40 00 00 02 6F 20
					39 00 00 00 00 00 04 C3 3F 32 FF
					39 00 00 40 00 00 02 6F 26
					39 00 00 00 00 00 04 C3 3F 32 FF
					39 00 00 40 00 00 02 6F 29
					39 00 00 00 00 00 04 C3 11 11 01
					39 00 00 40 00 00 02 6F 2C
					39 00 00 00 00 00 04 C3 00 00 00
					39 00 00 40 00 00 02 6F 31
					39 00 00 00 00 00 03 C3 AA 02
					39 00 00 40 00 00 02 6F 33
					39 00 00 00 00 00 03 C3 AA 02
					39 00 00 40 00 00 02 6F 04
					39 00 00 40 00 00 02 C3 19
					39 00 00 40 00 00 02 6F 09
					39 00 00 40 00 00 02 C3 19
					39 00 00 40 00 00 02 6F 01
					39 00 00 40 00 00 02 C3 09
					39 00 00 40 00 00 02 6F 06
					39 00 00 40 00 00 02 C3 09
					39 00 00 40 00 00 02 6F 02
					39 00 00 00 00 00 03 C3 02 81
					39 00 00 40 00 00 02 6F 08
					39 00 00 00 00 00 02 C3 81
					/* Video trim setting end */
					39 00 00 40 00 00 06 F0 55 AA 52 08 00
					39 00 00 40 00 00 02 6F DF
					39 00 00 40 00 00 06 B2 00 01 00 26 01
					39 00 00 40 00 00 02 6F 2B
					39 00 00 40 00 00 15 B2 00 00 2E B3 2E B3 2E B3 3F FF 3F FF 3F FF 3F FF 3F FF 3F FF
					39 00 00 40 00 00 02 6F 34
					39 00 00 00 00 00 15 B3 00 01 00 05 00 05 00 26 00 26 00 26 00 26 00 26 00 26 00 26
					39 00 00 00 5A 00 02 11 00
					39 00 00 00 00 00 02 29 00
					39 00 00 40 00 00 13 A3 84 02 2B 02 2B 02 04 B5 02 03 00 03 00 00 00 00 00 00
					39 00 00 40 00 00 02 6F 12
					39 00 00 40 00 00 0E A3 01 00 9D 00 00 AA 00 00 00 00 00 00 00
					39 00 00 40 00 00 02 6F 53
					39 00 00 40 00 00 0E A3 02 04 B5 02 03 00 0C 00 00 00 00 00 00
					39 00 00 40 00 00 02 6F 60
					39 00 00 00 00 00 0E A3 01 00 9D 00 00 AA 00 00 00 00 00 00 00
		          ];
				qcom,mdss-dsi-on-command-state = "dsi_lp_mode";
				qcom,mdss-dsi-timing-switch-command = [
					39 00 00 40 00 00 06 F0 55 AA 52 08 08
					39 00 00 40 00 00 02 6F 10
					39 00 00 40 00 00 11 B7 00 00 00 00 00 00 00 00 09 E2 09 E2 0A 14 0A 14
					39 00 00 40 00 00 02 6F 20
					39 00 00 40 00 00 0F B7 0A 5A 0A 5A 0A 5A 0A 5A 0A B2 0A B2 0B FA
					39 00 00 40 00 00 02 6F 23
					39 00 00 40 00 00 15 C1 0C FF CC FF FF CC FF FF CC FF FF EE 7F 7F EE 7F 7F CF 7F 30
					39 00 00 40 00 00 02 2F 02
					39 00 00 40 00 00 34 A9 01 00 2F 00 00 02 01 00 A2 00 27 03 02 01 DD 02 03 09 06 00 00 00 00 00 00 02 04 B5 01 03 00 00 11 00 00 00 00 00 01 00 9D 00 00 AA 00 00 00 00 00 00 00
					39 00 00 40 00 00 13 A3 84 02 2B 02 2B 02 04 B5 02 03 00 13 00 00 00 00 00 00
					39 00 00 40 00 00 02 6F 12
					39 00 00 40 00 00 0E A3 01 00 9D 00 00 AA 00 00 00 00 00 00 00
					39 00 00 40 00 00 02 6F 53
					39 00 00 40 00 00 0E A3 02 04 B5 02 03 00 1C 00 00 00 00 00 00
					39 00 00 40 00 00 02 6F 60
					39 00 00 00 00 00 0E A3 01 00 9D 00 00 AA 00 00 00 00 00 00 00
				];
				qcom,mdss-dsi-timing-switch-command-state = "dsi_hs_mode";
				qcom,mdss-dsi-timing-switch-hdbv-command = [
					39 00 00 40 00 00 06 F0 55 AA 52 08 08
					39 00 00 40 00 00 02 6F 10
					39 00 00 40 00 00 11 B7 00 00 00 00 00 00 00 00 09 E2 09 E2 0A 14 0A 14
					39 00 00 40 00 00 02 6F 20
					39 00 00 40 00 00 0F B7 0A 5A 0A 5A 0A 5A 0A 5A 0A B2 0A B2 0B FA
					39 00 00 40 00 00 02 6F 23
					39 00 00 40 00 00 15 C1 0C FF CC FF FF CC FF FF CC FF FF EE 7F 7F EE 7F 7F CF 7F 30
					39 00 00 40 00 00 02 2F 02
					39 00 00 40 00 00 34 A9 01 00 2F 00 00 02 01 00 A2 00 27 03 02 01 DD 02 03 09 06 00 00 00 00 00 00 02 04 B5 01 03 00 00 14 00 00 00 00 00 01 00 9D 00 00 AA 00 00 00 00 00 00 00
					39 00 00 40 00 00 13 A3 84 02 2B 02 2B 02 04 B5 02 03 00 13 00 00 00 00 00 00
					39 00 00 40 00 00 02 6F 12
					39 00 00 40 00 00 0E A3 01 00 9D 00 00 AA 00 00 00 00 00 00 00
					39 00 00 40 00 00 02 6F 53
					39 00 00 40 00 00 0E A3 02 04 B5 02 03 00 1C 00 00 00 00 00 00
					39 00 00 40 00 00 02 6F 60
					39 00 00 00 00 00 0E A3 01 00 9D 00 00 AA 00 00 00 00 00 00 00
				];
				qcom,mdss-dsi-timing-switch-hdbv-command-state = "dsi_hs_mode";
				qcom,mdss-dsi-nolp-command = [
					39 00 00 00 01 00 03 51 00 00
					/* AOD OFF */
					05 00 00 00 00 00 01 38
				];
				qcom,mdss-dsi-nolp-command-update = <0x51 0 2>;
				qcom,mdss-dsi-nolp-command-state = "dsi_hs_mode";

				mi,mdss-dsi-doze-hbm-command = [
					/* AOD OFF */
					39 00 00 00 01 00 03 51 02 B2
					39 00 00 00 00 00 01 38
				];
				mi,mdss-dsi-doze-hbm-command-state = "dsi_hs_mode";
				mi,mdss-dsi-doze-lbm-command = [
					/* AOD OFF */
					39 00 00 00 01 00 03 51 00 65
					39 00 00 00 00 00 01 38
				];
				mi,mdss-dsi-doze-lbm-command-state = "dsi_hs_mode";

				mi,mdss-dsi-doze-suspend-hbm-command = [
					/* AOD ON */
					39 00 00 00 29 00 34 A9 01 00 39 00 00 00 01 00 A2 00 27 03 02 01 DD 02 03 00 00 00 00 00 00 00 00 02 04 B5 01 03 00 00 05 00 00 00 00 00 01 00 9D 00 00 AA 00 00 00 00 00 00 00
					39 00 00 40 00 00 13 A3 84 02 2B 02 2B 02 04 B5 02 03 00 03 00 00 00 00 00 00
					39 00 00 40 00 00 02 6F 12
					39 00 00 40 00 00 0E A3 01 00 9D 00 00 AA 00 00 00 00 00 00 00
					39 00 00 40 00 00 02 6F 53
					39 00 00 40 00 00 0E A3 02 04 B5 02 03 00 0C 00 00 00 00 00 00
					39 00 00 40 00 00 02 6F 60
					39 00 00 40 00 00 0E A3 01 00 9D 00 00 AA 00 00 00 00 00 00 00
					39 00 00 40 00 00 03 51 02 B2
					39 00 00 40 00 00 02 6F 04
					39 00 00 00 00 00 03 51 3F FF
				];
				mi,mdss-dsi-doze-suspend-hbm-command-state = "dsi_lp_mode";

				mi,mdss-dsi-doze-suspend-lbm-command = [
					/* AOD ON */
					39 00 00 00 29 00 34 A9 01 00 39 00 00 00 01 00 A2 00 27 03 02 01 DD 02 03 00 00 00 00 00 00 00 00 02 04 B5 01 03 00 00 05 00 00 00 00 00 01 00 9D 00 00 AA 00 00 00 00 00 00 00
					39 00 00 40 00 00 13 A3 84 02 2B 02 2B 02 04 B5 02 03 00 03 00 00 00 00 00 00
					39 00 00 40 00 00 02 6F 12
					39 00 00 40 00 00 0E A3 01 00 9D 00 00 AA 00 00 00 00 00 00 00
					39 00 00 40 00 00 02 6F 53
					39 00 00 40 00 00 0E A3 02 04 B5 02 03 00 0C 00 00 00 00 00 00
					39 00 00 40 00 00 02 6F 60
					39 00 00 40 00 00 0E A3 01 00 9D 00 00 AA 00 00 00 00 00 00 00
					39 00 00 40 00 00 03 51 00 65
					39 00 00 40 00 00 02 6F 04
					39 00 00 00 00 00 03 51 05 54
				];
				mi,mdss-dsi-doze-suspend-lbm-command-state = "dsi_lp_mode";

				mi,mdss-dsi-doze-hbm-nolp-command = [
					/* AOD OFF */
					39 00 00 00 01 00 03 51 02 B2
					39 00 00 00 00 00 01 38
				];
				mi,mdss-dsi-doze-hbm-nolp-command-state = "dsi_lp_mode";

				mi,mdss-dsi-doze-lbm-nolp-command = [
					/* AOD OFF */
					39 00 00 00 01 00 03 51 00 65
					39 00 00 00 00 00 01 38
				];
				mi,mdss-dsi-doze-lbm-nolp-command-state = "dsi_lp_mode";
			};
		};
	};
};

&dsi_p12x_42_02_0a_dsc_cmd {
	qcom,panel-supply-entries = <&dsi_panel_pwr_supply_p12x>;
	qcom,mdss-dsi-bl-pmic-control-type = "bl_ctrl_dcs";
	qcom,mdss-dsi-bl-min-level = <5>;
	qcom,mdss-dsi-bl-max-level = <16383>;
	qcom,bl-dsc-cmd-state = "dsi_hs_mode";
	qcom,mdss-brightness-max-level = <16383>;
	qcom,mdss-brightness-init-level = <938>;
	qcom,platform-reset-gpio = <&tlmm 98 0>;

	mi,max-brightness-normal = <6750>;

	mi,panel-build-id-read-needed;
	mi,panel-build-id-read-length = <1>;
	mi,mdss-dsi-panel-build-id-read-command = [06 01 00 01 00 00 01 DA];
	mi,mdss-dsi-panel-build-id-read-command-state = "dsi_hs_mode";

	qcom,mdss-dsi-panel-vsync-delay;
	qcom,ulps-enabled;
	qcom,dsi-select-clocks = "pll_byte_clk0", "pll_dsi_clk0";
	qcom,mdss-dsi-clk-strength = <0x88>;
};
